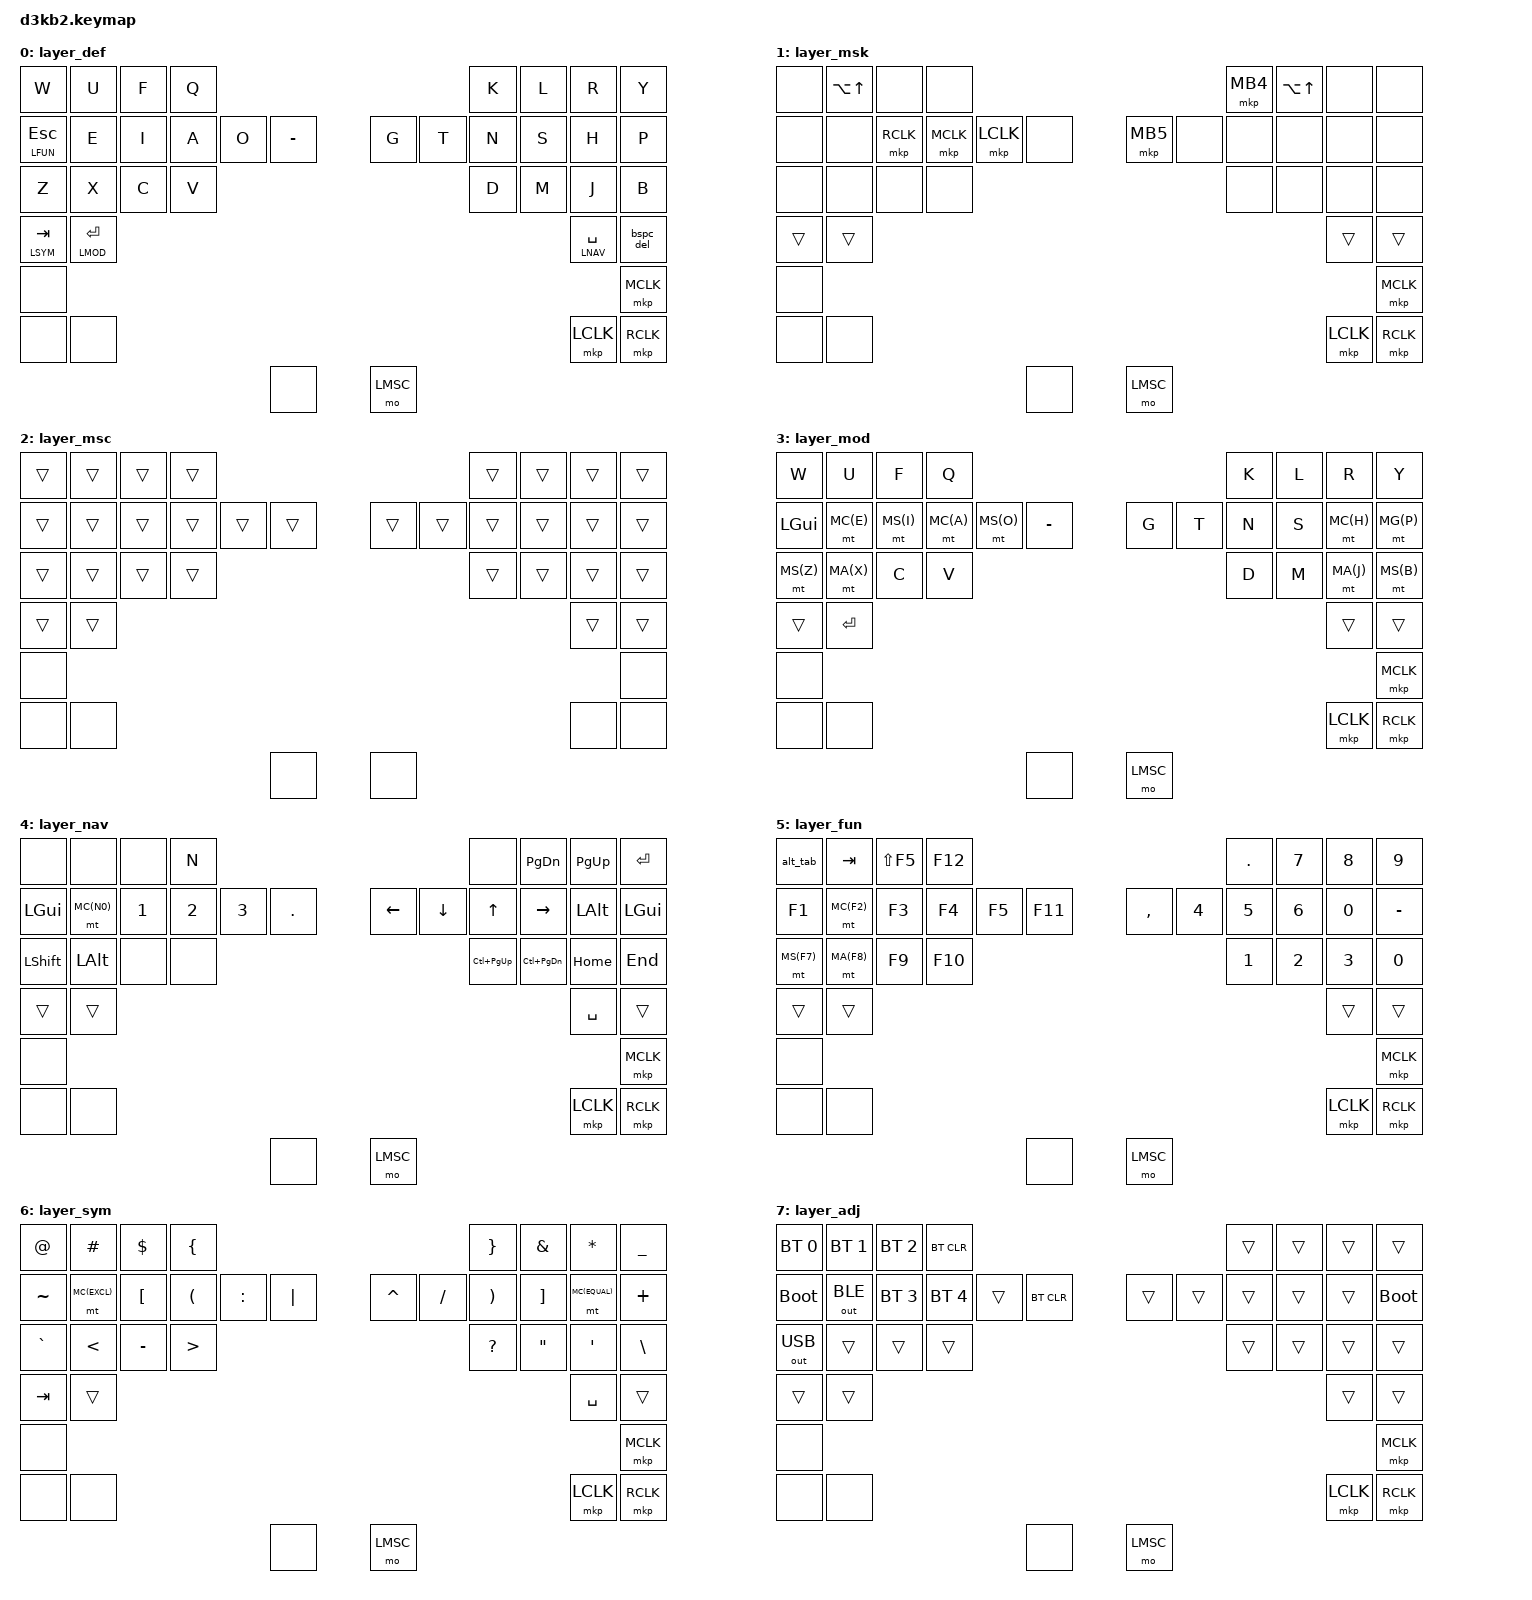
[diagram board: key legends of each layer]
#include <behaviors.dtsi>
#include <dt-bindings/zmk/keys.h>
#include <dt-bindings/zmk/bt.h>
#include <dt-bindings/zmk/outputs.h>
#include <dt-bindings/zmk/mouse.h>


/*
        ////////////////////
        // layer settings //
        ////////////////////
*/
#define LDEF 0 // default
#define LMSK 1 // mouse keys
#define LMSC 2 // mouse scroll
#define LMOD 3 // modifier
#define LNAV 4 // navigation
#define LFUN 5 // function
#define LSYM 6 // symbol
#define LADJ 7 // adjust
/{
    keymap {
        compatible = "zmk,keymap";
        layer_def:layer_def{};
        layer_msk:layer_msk{};
        layer_msc:layer_msc{};
        layer_mod:layer_mod{};
        layer_nav:layer_nav{};
        layer_fun:layer_fun{};
        layer_sym:layer_sym{};
        layer_adj:layer_adj{};
    };
};


/*
        ////////////////////////////////////
        // trackball listener & behaviors //
        ////////////////////////////////////
*/

/{
  trackball_listener_mmv { // mouse move
          compatible = "zmk,input-behavior-listener";
          device = <&trackball>;
          layers = <LDEF LMOD LMSK>;
          evt-type = <INPUT_EV_REL>;
          x-input-code = <INPUT_REL_X>;
          y-input-code = <INPUT_REL_Y>;
          scale-multiplier = <1>;
          scale-divisor = <1>;
          bindings = <&ib_tog_layer LMSK>; // layer auto activate
  };
  ib_tog_layer: ib_tog_layer { // layer dectivate time
      compatible = "zmk,input-behavior-tog-layer";
      #binding-cells = <1>;
      time-to-live-ms = <750>;
  };
  trackball_listener_msc { // mouse scroll
          compatible = "zmk,input-behavior-listener";
          device = <&trackball>;
          layers = <LMSC LSYM>; 
          evt-type = <INPUT_EV_REL>;
          x-input-code = <INPUT_REL_MISC>;
          y-input-code = <INPUT_REL_WHEEL>;
          y-invert;
          bindings = <&ib_wheel_scaler 1 16>;
  };
  ib_wheel_scaler: ib_wheel_scaler { // scroll config
      compatible = "zmk,input-behavior-scaler";
      #binding-cells = <2>;
      evt-type = <INPUT_EV_REL>;
      input-code = <INPUT_REL_WHEEL>;
  };
};

/*
        //////////////
        // encoders //
        //////////////
*/
/ {
    sensors: sensors {
        compatible = "zmk,keymap-sensors";
        sensors = <&encoder>;
        triggers-per-rotation = <18>;
    };
};

// scroll behavior for encoder
#define ZMK_MOUSE_ENC_SCRL_VAL 70
#define SCRL_ENC_UP MOVE_Y(ZMK_MOUSE_ENC_SCRL_VAL)
#define SCRL_ENC_DOWN MOVE_Y(-ZMK_MOUSE_ENC_SCRL_VAL)
#define SCRL_ENC_LEFT MOVE_X(-ZMK_MOUSE_ENC_SCRL_VAL)
#define SCRL_ENC_RIGHT MOVE_X(ZMK_MOUSE_ENC_SCRL_VAL)
#define ZMK_MOUSE_ENC_SCRL_FAST_VAL 140
#define SCRL_ENC_FAST_UP MOVE_Y(ZMK_MOUSE_ENC_SCRL_FAST_VAL)
#define SCRL_ENC_FAST_DOWN MOVE_Y(-ZMK_MOUSE_ENC_SCRL_FAST_VAL)
#define SCRL_ENC_FAST_LEFT MOVE_X(-ZMK_MOUSE_ENC_SCRL_FAST_VAL)
#define SCRL_ENC_FAST_RIGHT MOVE_X(ZMK_MOUSE_ENC_SCRL_FAST_VAL)
/{
    behaviors{
        scroll_enc_du: scroll_enc_du {
            compatible = "zmk,behavior-sensor-rotate";
            #sensor-binding-cells = <0>;
            bindings = <&msc SCRL_ENC_DOWN>, <&msc SCRL_ENC_UP>;
            tap-ms = <20>;
        };
        scroll_enc_lr: scroll_enc_lr {
            compatible = "zmk,behavior-sensor-rotate";
            #sensor-binding-cells = <0>;
            bindings = <&msc SCRL_ENC_LEFT>, <&msc SCRL_ENC_RIGHT>;
            tap-ms = <20>;
        };
    };
};



/*
        //////////////////////////
        // custom key behaviors //
        //////////////////////////
*/
// macro for mod tap
#define MC(X) LCTRL X
#define MS(X) LSHFT X
#define MA(X) LALT X
#define MG(X) LGUI X

// modify existing behaviors
&mt {
    tapping-term-ms = <175>;
    flavor = "tap-preferred";
};
&lt {
    tapping-term-ms = <175>;
    flavor = "balanced";
};
&sk {
    quick-release;
};
&caps_word {
    continue-list = <UNDERSCORE MINUS BACKSPACE>;
};

/ {
    behaviors {
        // original behaviors
        smo: sticky_key_and_mo {
            // &smo LFUN LSHFT : tap to sticky shift, hold to function layer
            compatible = "zmk,behavior-hold-tap";
            #binding-cells = <2>;
            flavor = "hold-preferred";
            tapping-term-ms = <200>;
            bindings = <&mo>, <&sk>;
        };
        bspc_del: bspc_and_del{
            compatible = "zmk,behavior-mod-morph";
            #binding-cells = <0>;
            bindings = <&kp BSPC>, <&kp DEL>;
            mods = <(MOD_LSFT|MOD_RSFT)>;
        };

        // behaviors for mod layer
        lth: layer_tap_hold_flavor {
            compatible = "zmk,behavior-hold-tap";
            #binding-cells = <2>;
            flavor = "hold-preferred";
            tapping-term-ms = <200>;
            bindings = <&mo>, <&kp>;
        };
        lm: momentally_layer_and_modifier {
            // activate momentally layer and press (modifier) key
            // &lm LMOD LCTRL : activate modifier layer with LCTRL hold
            compatible = "zmk,behavior-macro-two-param";
            wait-ms = <0>;
            tap-ms = <0>;
            #binding-cells = <2>;
            bindings
                = <&macro_param_1to1>
                , <&macro_press &mo MACRO_PLACEHOLDER>
                , <&macro_param_2to1>
                , <&macro_press &kp MACRO_PLACEHOLDER>
                , <&macro_pause_for_release>
                , <&macro_param_2to1>
                , <&macro_release &kp MACRO_PLACEHOLDER>
                , <&macro_param_1to1>
                , <&macro_release &mo MACRO_PLACEHOLDER>
                ;
        };
    };

    macros {
        // alt+tab on tap, continue to press alt on hold. 
        alt_tab: alt_tab {
            compatible = "zmk,behavior-macro";
            #binding-cells = <0>;
            wait-ms = <0>;
            tap-ms = <0>;
            bindings
                = <&macro_press &kp LALT>
                , <&macro_tap &kp TAB>
                , <&macro_pause_for_release>
                , <&macro_release &kp LALT>
                ;
        };
    };
};


/*
        ////////////
        // combos //
        ////////////
*/

/ {
    combos{
        compatible = "zmk,combos";
        timeout-ms = <150>;

        // T ** ** 00 01 02 03 || 04 05 06 07 ** **
        // M 08 09 10 11 12 13 || 14 15 16 17 18 19
        // B ** 20 21 22 23 ** || ** 24 25 26 27 **
        // Th            28 29 || 30 31


        //adj
        combo_LR_1M {
            key-positions = <8 19>;
            bindings = <&mo LADJ>;
            slow-release;
        };

        //left basic
        combo_L_23T {
            key-positions = <0 1>;
            bindings = <&kp ESC>;
        };

        // right basic
        combo_R_4TM {
            key-positions = <5 15>;
            bindings = <&kp COMMA>;
        };
        combo_R_3TM {
            key-positions = <6 16>;
            bindings = <&kp DOT>;
        };
        combo_R_2TM {
            key-positions = <7 17>;
            bindings = <&kp SEMI>;
        };
        combo_R_23B {
            key-positions = <25 26>;
            bindings = <&kp PRCNT>;
            layers = < LDEF LMOD LNAV LSYM LADJ>;
        };

        // thum
        combo_L_thum {
            key-positions = <28 29>;
            bindings = <&smo LFUN LSHFT>;
        };
        combo_R_thum {
            key-positions = <30 31>;
            bindings = <&caps_word>;
        };

        // thum mod
        combo_L_1M_thum { // ctrl
            key-positions = <9 29>;
            bindings = <&lm LMOD LCTRL>;
            slow-release;
        };
        combo_L_1B_thum { // shift
            key-positions = <20 29>;
            bindings = <&lm LMOD LSHFT>;
            slow-release;
        };
        combo_L_0M_thum { // gui
            key-positions = <8 29>;
            bindings = <&lm LMOD LGUI>;
            slow-release;
        };
        combo_L_3M_thum { // ctrl
            key-positions = <11 29>;
            bindings = <&lm LMOD LCTRL>;
            slow-release;
        };

    };
};

/*
        /////////////
        // keymaps //
        /////////////
*/
&layer_def {

    bindings = <
                     &kp W  &kp U &kp F &kp Q           &kp K &kp L &kp R &kp Y   
  &lt LFUN ESC &kp E &kp I  &kp A &kp O &kp MINUS       &kp G &kp T &kp N &kp S &kp H &kp P
               &kp Z &kp X  &kp C &kp V                       &kp D &kp M &kp J &kp B 
                   &lt LSYM TAB &lth LMOD RET           &lt LNAV SPACE &bspc_del

                     &none                               &mkp MCLK
                &none       &none              &mkp LCLK           &mkp RCLK
                     &none                               &mo LMSC
        >;
        sensor-bindings = <&scroll_enc_du>;
};
&layer_msk {
    bindings = <
                     &none     &kp LA(UP) &none     &none     &mkp MB4 &kp LA(UP)  &none &none   
         &none &none &mkp RCLK &mkp MCLK  &mkp LCLK &none     &mkp MB5 &none       &none &none &none &none
               &none &none     &none      &none                        &none       &none &none &none 
                               &trans     &trans                       &trans      &trans

                     &none                               &mkp MCLK
                &none       &none              &mkp LCLK           &mkp RCLK
                     &none                               &mo LMSC
        >;
            sensor-bindings = <&scroll_enc_lr>;
};
&layer_msc {
    bindings = <
                      &trans  &trans &trans &trans     &trans &trans &trans &trans   
        &trans &trans &trans  &trans &trans &trans     &trans &trans &trans &trans &trans &trans
               &trans &trans  &trans &trans                   &trans &trans &trans &trans 
                              &trans &trans                   &trans  &trans
                     &none                 &none
                &none       &none    &none       &none
                     &none                 &none
        >;
            sensor-bindings = <&scroll_enc_lr>;
};
&layer_mod {

    bindings = <
                    &kp W      &kp U     &kp F     &kp Q        &kp K &kp L &kp R &kp Y   
&kp LGUI  &mt MC(E) &mt MS(I)  &mt MC(A) &mt MS(O) &kp MINUS    &kp G &kp T &kp N &kp S     &mt MC(H) &mt MG(P)
          &mt MS(Z) &mt MA(X)  &kp C     &kp V                        &kp D &kp M &mt MA(J) &mt MS(B) 
                                 &trans   &kp RET               &trans &trans

                     &none                               &mkp MCLK
                &none       &none              &mkp LCLK           &mkp RCLK
                     &none                               &mo LMSC
        >;
        sensor-bindings = <&scroll_enc_du>;
};

&layer_nav {
    bindings = <
                    &none         &none       &none     &kp N       &none    &kp PG_DN     &kp PG_UP     &kp RET
&kp LGUI &mt MC(N0) &kp N1        &kp N2      &kp N3    &kp DOT     &kp LEFT &kp DOWN      &kp UP        &kp RIGHT &kp LALT &kp LGUI 
         &kp LSHFT  &kp LALT      &none       &none                          &kp LC(PG_UP) &kp LC(PG_DN) &kp HOME  &kp END    
                                  &trans    &trans                           &kp SPACE   &trans

                     &none                               &mkp MCLK
                &none       &none              &mkp LCLK           &mkp RCLK
                     &none                               &mo LMSC
        >;
        sensor-bindings = <&scroll_enc_du>;
};
&layer_fun {
    bindings = <
                   &alt_tab    &kp TAB &kp LS(F5) &kp F12     &kp DOT   &kp N7 &kp N8 &kp N9      
&kp F1  &mt MC(F2) &kp F3      &kp F4  &kp F5     &kp F11     &kp COMMA &kp N4 &kp N5 &kp N6 &kp N0 &kp MINUS   
        &mt MS(F7) &mt MA(F8)  &kp F9  &kp F10                          &kp N1 &kp N2 &kp N3 &kp N0      
                       &trans  &trans                &trans &trans

                     &none                               &mkp MCLK
                &none       &none              &mkp LCLK           &mkp RCLK
                     &none                               &mo LMSC
        >;
        sensor-bindings = <&scroll_enc_du>;
};
&layer_sym {
    bindings = <
                       &kp AT   &kp HASH   &kp DLLR  &kp LBRC    &kp RBRC   &kp AMPS   &kp STAR  &kp UNDER   
&kp TILDE &mt MC(EXCL) &kp LBKT &kp LPAR   &kp COLON &kp PIPE    &kp CARET  &kp FSLH   &kp RPAR  &kp RBKT  &mt MC(EQUAL) &kp PLUS 
          &kp GRAVE    &kp LT   &kp MINUS  &kp GT                           &kp QMARK  &kp DQT   &kp SQT   &kp BSLH 
                                &kp TAB    &trans                           &kp SPACE   &trans

                     &none                               &mkp MCLK
                &none       &none              &mkp LCLK           &mkp RCLK
                     &none                               &mo LMSC
        >;
        sensor-bindings = <&scroll_enc_du>;
};
&layer_adj {
    bindings = <
                         &bt BT_SEL 0 &bt BT_SEL 1 &bt BT_SEL 2 &bt BT_CLR       &trans      &trans      &trans      &trans      
&bootloader &out OUT_BLE &bt BT_SEL 3 &bt BT_SEL 4 &trans       &bt BT_CLR       &trans      &trans      &trans      &trans      &trans      &bootloader
            &out OUT_USB &trans       &trans       &trans                                    &trans      &trans      &trans      &trans      
                       &trans  &trans                &trans &trans

                     &none                               &mkp MCLK
                &none       &none              &mkp LCLK           &mkp RCLK
                     &none                               &mo LMSC
        >;
        sensor-bindings = <&scroll_enc_du>;
};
